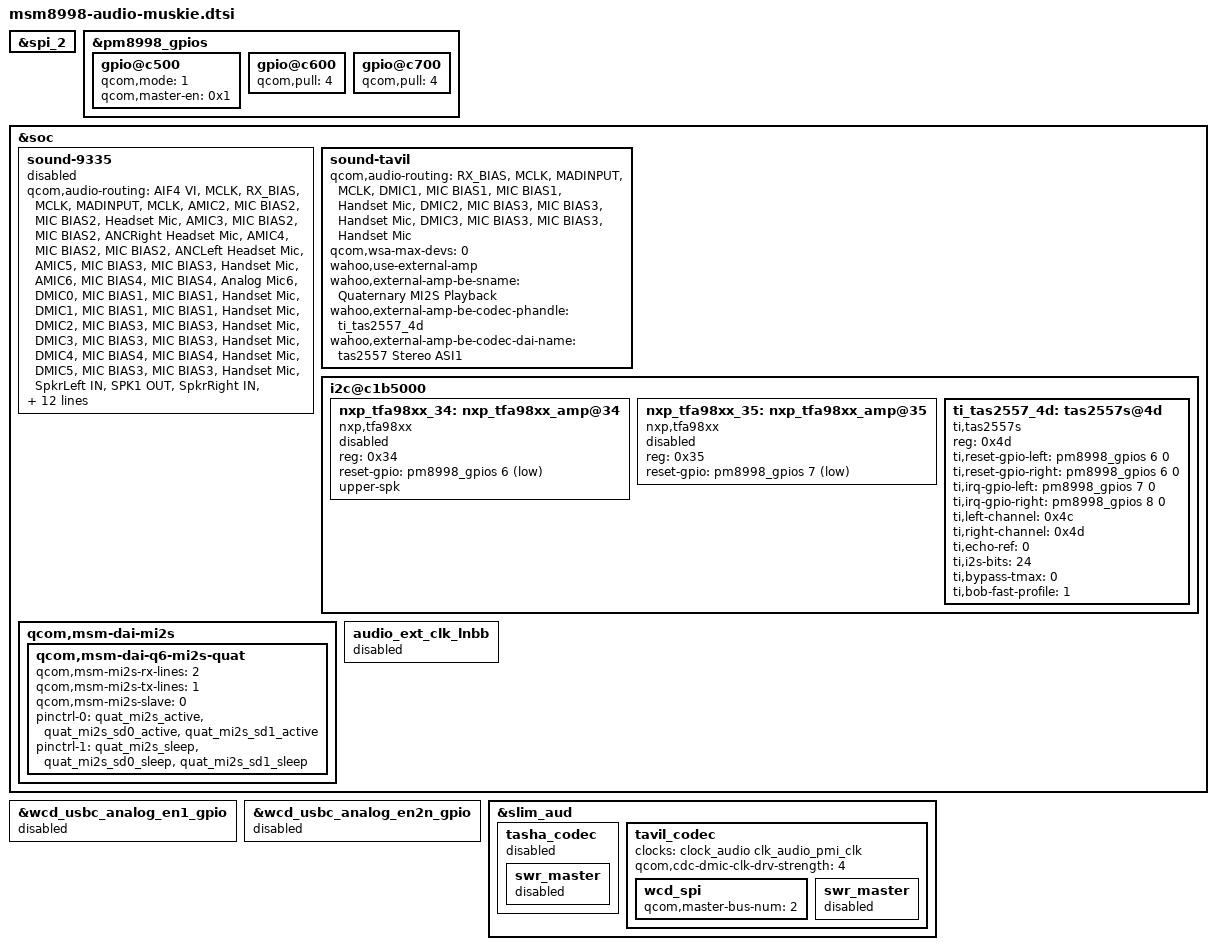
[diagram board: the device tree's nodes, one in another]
&spi_2 {
	status = "ok";
};

&pm8998_gpios {

		gpio@c500 { /* pm8998 gpio 6 */
			qcom,mode = <1>; /* output mode */
			qcom,master-en = <0x1>;
		};

		gpio@c600 { /* pm8998 gpio 7 */
			qcom,pull = <4>; /* PULL DOWN */
		};

		gpio@c700 { /* pm8998 gpio 8 */
			qcom,pull = <4>; /* PULL DOWN */
		};
};

&soc {
	sound-9335 {
		status = "disabled";
		qcom,audio-routing =
			"AIF4 VI", "MCLK",
			"RX_BIAS", "MCLK",
			"MADINPUT", "MCLK",
			"AMIC2", "MIC BIAS2",
			"MIC BIAS2", "Headset Mic",
			"AMIC3", "MIC BIAS2",
			"MIC BIAS2", "ANCRight Headset Mic",
			"AMIC4", "MIC BIAS2",
			"MIC BIAS2", "ANCLeft Headset Mic",
			"AMIC5", "MIC BIAS3",
			"MIC BIAS3", "Handset Mic",
			"AMIC6", "MIC BIAS4",
			"MIC BIAS4", "Analog Mic6",
			"DMIC0", "MIC BIAS1",
			"MIC BIAS1", "Handset Mic",
			"DMIC1", "MIC BIAS1",
			"MIC BIAS1", "Handset Mic",
			"DMIC2", "MIC BIAS3",
			"MIC BIAS3", "Handset Mic",
			"DMIC3", "MIC BIAS3",
			"MIC BIAS3", "Handset Mic",
			"DMIC4", "MIC BIAS4",
			"MIC BIAS4", "Handset Mic",
			"DMIC5", "MIC BIAS3",
			"MIC BIAS3", "Handset Mic",
			"SpkrLeft IN", "SPK1 OUT",
			"SpkrRight IN", "SPK2 OUT";

		qcom,msm-mbhc-hphl-swh = <1>; /* for NO Audio Jack */
		qcom,msm-mbhc-gnd-swh = <1>; /* for NO Audio Jack */
		qcom,wsa-max-devs = <0>; /* No wsa device */

		wahoo,use-external-amp;
		wahoo,external-amp-be-sname = "Quaternary MI2S Playback",
					      "Tertiary MI2S Playback";
		wahoo,external-amp-be-codec-phandle = <&nxp_tfa98xx_34>,
						      <&nxp_tfa98xx_35>;
		wahoo,external-amp-be-codec-dai-name = "tfa98xx-aif-7-34",
						       "tfa98xx-aif-7-35";
	};

	sound-tavil {
		qcom,audio-routing =
			"RX_BIAS", "MCLK",
			"MADINPUT", "MCLK",
			"DMIC1", "MIC BIAS1",
			"MIC BIAS1", "Handset Mic",
			"DMIC2", "MIC BIAS3",
			"MIC BIAS3", "Handset Mic",
			"DMIC3", "MIC BIAS3",
			"MIC BIAS3", "Handset Mic";

		qcom,wsa-max-devs = <0>; /* No wsa device */

		wahoo,use-external-amp;
		wahoo,external-amp-be-sname = "Quaternary MI2S Playback";

		wahoo,external-amp-be-codec-phandle = <&ti_tas2557_4d>;

		wahoo,external-amp-be-codec-dai-name = "tas2557 Stereo ASI1";
	};

	i2c@c1b5000 { /* i2c_7 */
		nxp_tfa98xx_34: nxp_tfa98xx_amp@34 {
				compatible = "nxp,tfa98xx";
				reg = <0x34>;
				reset-gpio = <&pm8998_gpios 6 0x1>;
				upper-spk; /* left */
				status = "disabled";
		};

		nxp_tfa98xx_35: nxp_tfa98xx_amp@35 {
				compatible = "nxp,tfa98xx";
				reg = <0x35>;
				reset-gpio = <&pm8998_gpios 7 0x1>;
				status = "disabled";
		};

		ti_tas2557_4d: tas2557s@4d {
				#sound-dai-cells = <1>;
				compatible = "ti,tas2557s";
				reg = <0x4d>;
				ti,reset-gpio-left = <&pm8998_gpios 6 0>;
				ti,reset-gpio-right = <&pm8998_gpios 6 0>;
				ti,irq-gpio-left = <&pm8998_gpios 7 0>;
				ti,irq-gpio-right = <&pm8998_gpios 8 0>;
				ti,left-channel = <0x4c>;
				ti,right-channel = <0x4d>;
				ti,echo-ref = <0>;   /* 0, left channel; 1, right channel; 2, both */
				ti,i2s-bits = <24>;   /* support 16, 24, 32 */
				ti,bypass-tmax = <0>;   /* 0, not bypass; 1, bypass */
				ti,bob-fast-profile = <1>; /* 1:voice_handset */
				status = "ok";
		};
	};

	qcom,msm-dai-mi2s {
		qcom,msm-dai-q6-mi2s-quat {
			qcom,msm-mi2s-rx-lines = <2>; /* SD1 (1 << 1) */
			qcom,msm-mi2s-tx-lines = <1>; /* SD0 (0 << 0) */
			qcom,msm-mi2s-slave = <0>;
			pinctrl-names = "default", "sleep";
			pinctrl-0 = <&quat_mi2s_active
				     &quat_mi2s_sd0_active
				     &quat_mi2s_sd1_active>;
			pinctrl-1 = <&quat_mi2s_sleep
				     &quat_mi2s_sd0_sleep
				     &quat_mi2s_sd1_sleep>;
		};
	};

	audio_ext_clk_lnbb {
		status = "disabled";
	};
};

/* msm_cdc_pinctrl@59 */
&wcd_usbc_analog_en1_gpio {
	status = "disabled";
};

/* msm_cdc_pinctrl@60 */
&wcd_usbc_analog_en2n_gpio {
	status = "disabled";
};

&slim_aud {
	tasha_codec {
		status = "disabled";
		swr_master {
			status = "disabled";
		};
	};

	tavil_codec {
		clocks = <&clock_audio clk_audio_pmi_clk>;
		qcom,cdc-dmic-clk-drv-strength = <4>; /* 4mA */
		wcd_spi {
			qcom,master-bus-num = <2>;
		};
		swr_master {
			status = "disabled";
		};
	};
};

